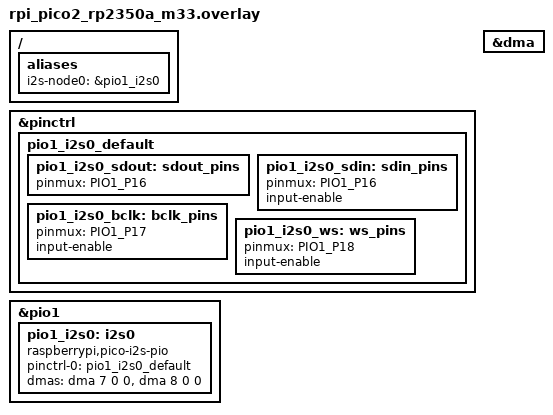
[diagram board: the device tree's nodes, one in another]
/*
 * Copyright (c) 2026 Robin Sachsenweger Ballantyne <makenenjoy@gmail.com>
 *
 * SPDX-License-Identifier: Apache-2.0
 */

#include <dt-bindings/pinctrl/rpi-pico-rp2350a-pinctrl.h>
#include <zephyr/dt-bindings/dma/rpi-pico-dma-rp2350.h>

/ {
	aliases {
		i2s-node0 = &pio1_i2s0;
	};
};

&pinctrl {
	pio1_i2s0_default: pio1_i2s0_default {
		pio1_i2s0_sdout: sdout_pins {
			pinmux = <PIO1_P16>;
		};

		pio1_i2s0_sdin: sdin_pins {
			pinmux = <PIO1_P16>;
			input-enable;
		};

		pio1_i2s0_bclk: bclk_pins {
			pinmux = <PIO1_P17>;
			input-enable;
		};

		pio1_i2s0_ws: ws_pins {
			pinmux = <PIO1_P18>;
			input-enable;
		};
	};
};

&pio1 {
	status = "okay";

	pio1_i2s0: i2s0 {
		compatible = "raspberrypi,pico-i2s-pio";
		status = "okay";

		pinctrl-0 = <&pio1_i2s0_default>;
		pinctrl-names = "default";

		#address-cells = <1>;
		#size-cells = <0>;

		dmas = <&dma 7 0 0>,
		       <&dma 8 0 0>;
		dma-names = "tx", "rx";
	};
};

&dma {
	status = "okay";
};
